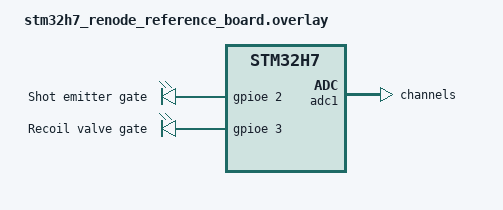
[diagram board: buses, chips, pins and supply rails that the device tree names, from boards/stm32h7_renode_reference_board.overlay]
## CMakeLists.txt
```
cmake_minimum_required(VERSION 3.20)
find_package(Zephyr REQUIRED HINTS $ENV{ZEPHYR_BASE})

project(trainer_fw LANGUAGES C)

target_include_directories(app PRIVATE
	src
	src/trigger
	src/weapon
	src/io
	src/control
	src/proto
	src/cfg
	src/can
	src/sys
	src/imu
	src/timesync
	src/strobe
)

target_sources(app PRIVATE
	src/main.c
	src/trigger/trigger_proc.c
	src/trigger/trigger_task.c
	src/weapon/rounds.c
	src/weapon/weapon_sm.c
	src/weapon/malfunction.c
	src/weapon/shotlog.c
	src/io/outputs.c
	src/io/inputs.c
	src/control/control.c
	src/proto/proto.c
	src/cfg/cfg.c
	src/cfg/cfg_store.c
	src/can/canlink.c
	src/can/lane.c
	src/sys/wdt.c
	src/sys/bit.c
	src/imu/imu_metrics.c
	src/imu/imu_task.c
	src/timesync/timesync.c
	src/strobe/strobe.c
	src/strobe/strobe_task.c
	src/shell/shell_cmds.c
)
```

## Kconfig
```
menu "Trainer weapon"

config TRAINER_MAG_CAPACITY
	int "Rounds in a full magazine"
	default 30
	range 1 100

config TRAINER_AUTO_RPM
	int "AUTO cadence (rounds per minute)"
	default 750
	range 600 900

config TRAINER_EMITTER_PULSE_US
	int "Shot emitter gate pulse width (us)"
	default 2000
	range 100 20000

config TRAINER_VALVE_PULSE_MS
	int "Recoil valve gate pulse width (ms)"
	default 20
	range 5 40

config TRAINER_TRIGGER_SAMPLE_HZ
	int "Trigger ADC sampling rate (Hz)"
	default 1000
	range 100 2000

config TRAINER_EVENT_QUEUE_LEN
	int "Control event queue length"
	default 16

config TRAINER_DEBUG_CMDS
	bool "Debug shell commands (stall threads, corrupt config)"
	help
	  Commands that deliberately break things to test the watchdog and
	  the config fallback (trainer stall, trainer cfg corrupt). Off in the
	  default image; the simulation and test image enables them with
	  app/debug.conf (scripts/build.sh).

endmenu

source "Kconfig.zephyr"
```

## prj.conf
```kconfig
# Kernel
CONFIG_MAIN_STACK_SIZE=2048
CONFIG_SYS_CLOCK_TICKS_PER_SEC=10000
CONFIG_ASSERT=y
CONFIG_POLL=y

# FPU for IMU metrics and the time-sync fit; several threads use it
CONFIG_FPU=y
CONFIG_FPU_SHARING=y

# Drivers
CONFIG_GPIO=y
CONFIG_ADC=y
CONFIG_INPUT=y
CONFIG_SENSOR=y
CONFIG_CAN=y
CONFIG_HWINFO=y

# State machine framework (hierarchical states)
CONFIG_SMF=y
CONFIG_SMF_ANCESTOR_SUPPORT=y

# Persistent configuration: settings on NVS in the QSPI storage partition
CONFIG_FLASH=y
CONFIG_FLASH_MAP=y
CONFIG_NVS=y
CONFIG_SETTINGS=y
CONFIG_SETTINGS_NVS=y
CONFIG_CRC=y

# Watchdog: one task-watchdog channel per thread, IWDG as hardware fallback
CONFIG_WATCHDOG=y
CONFIG_TASK_WDT=y
CONFIG_TASK_WDT_HW_FALLBACK=y
# control, trigger, IMU, CAN TX, lane, strobe
CONFIG_TASK_WDT_CHANNELS=6
CONFIG_REBOOT=y

# Diagnostics
CONFIG_LOG=y
# Deferred logging, but flushed promptly: wake the log thread on every
# message instead of the default 1 s batch, so test harnesses see events
# without a long delay.
CONFIG_LOG_PROCESS_TRIGGER_THRESHOLD=1
CONFIG_LOG_PROCESS_THREAD_SLEEP_MS=50
CONFIG_SHELL=y
CONFIG_SHELL_PROMPT_UART="trainer:~$ "
CONFIG_BOOT_BANNER_STRING="Booting trainer_fw"
```

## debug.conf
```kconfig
# Simulation and test image: added to prj.conf by scripts/build.sh
# (EXTRA_CONF_FILE). The default image (prj.conf alone) leaves these out.

# `trainer stall` (IT11, IT11b) and `trainer cfg corrupt` (IT08b)
CONFIG_TRAINER_DEBUG_CMDS=y
```

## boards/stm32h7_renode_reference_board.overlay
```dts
/*
 * Trainer weapon I/O on the STM32H7 Renode Reference Platform.
 *
 * Inputs use the board as it is: potentiometer (ADC1 INP2) = analog trigger,
 * SW1..SW4 (gpio-keys, INPUT_KEY_1..4) = selector, magazine, rack, tap.
 *
 * The emitter and recoil-valve gates go on free pins PE2/PE3. The board's
 * green LEDs sit on TIM3 PWM and have no LED model in Renode, so they are
 * not used. sim/trainer_io.repl attaches simulated LEDs to PE2/PE3.
 */

#include <zephyr/dt-bindings/adc/adc.h>
#include <zephyr/dt-bindings/sensor/lsm6dso.h>

/ {
	trainer_outputs {
		compatible = "gpio-leds";

		emitter_out: emitter {
			gpios = <&gpioe 2 GPIO_ACTIVE_HIGH>;
			label = "Shot emitter gate";
		};

		valve_out: valve {
			gpios = <&gpioe 3 GPIO_ACTIVE_HIGH>;
			label = "Recoil valve gate";
		};
	};

	aliases {
		trainer-emitter = &emitter_out;
		trainer-valve = &valve_out;
		trainer-status-red = &red_rgb_led;
		trainer-status-green = &green_rgb_led;
		trainer-status-blue = &blue_rgb_led;
	};
};

&gpioe {
	status = "okay";
};

/*
 * The board uses the maximum acquisition time (810.5 ADC cycles), which
 * limits trigger sampling well below 1 kHz. A short time is fine for a
 * low-impedance potentiometer and allows the 1 kHz trigger loop.
 */
&adc1 {
	channel@2 {
		zephyr,acquisition-time = <ADC_ACQ_TIME_DEFAULT>;
	};
};

/*
 * IMU for aim, cant and flinch: 208 Hz on both sensors (the board default is
 * a very low ODR). Full scale is chosen so recoil does not clip the gyro and
 * the accelerometer survives a recoil kick: +-16 g, +-2000 dps.
 */
&lsm6dso {
	accel-odr = <LSM6DSO_DT_ODR_208Hz>;
	gyro-odr = <LSM6DSO_DT_ODR_208Hz>;
	accel-range = <LSM6DSO_DT_FS_16G>;
	gyro-range = <LSM6DSO_DT_FS_2000DPS>;
};
```

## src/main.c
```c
/*
 * trainer_fw: firmware for an instrumented training weapon.
 *
 * Start order matters:
 *  1. reset reason + task watchdog
 *  2. outputs forced inactive before anything that can fire runs (SPEC R04)
 *  3. configuration (node ID) before CAN, because CAN IDs depend on it
 *  4. CAN + lane service, weapon control, emitter strobe, trigger sampling
 *  5. BIT, then INFO, so the lane learns the node is up and healthy
 */
#include <zephyr/app_version.h>
#include <zephyr/kernel.h>
#include <zephyr/logging/log.h>

#include "bit.h"
#include "canlink.h"
#include "cfg_store.h"
#include "control.h"
#include "imu_task.h"
#include "lane.h"
#include "outputs.h"
#include "strobe_task.h"
#include "trigger_task.h"
#include "wdt.h"

LOG_MODULE_REGISTER(main, LOG_LEVEL_INF);

int main(void)
{
	(void)wdt_init();
	LOG_INF("trainer_fw %s reset=%s%s%s", APP_VERSION_STRING,
		wdt_reset_reason_name(wdt_reset_reason()),
		(wdt_last_stalled_thread()[0] != '\0') ? " thread=" : "", wdt_last_stalled_thread());

	int rc = outputs_init();

	bit_note_outputs(rc);
	if (rc != 0) {
		LOG_ERR("outputs init failed (%d)", rc);
	}

	(void)cfg_store_init();
	uint8_t node = cfg_store_node_id();

	if (canlink_init(node) == 0) {
		lane_start(node);
	}

	control_start();
	strobe_start();

	rc = trigger_task_start();
	bit_note_adc(rc);

	/* A missing IMU is reported by BIT; the weapon then sits in FAULT. */
	(void)imu_task_start();

	/* Let the trigger take a few samples so BIT can see whether it is at rest. */
	k_sleep(K_MSEC(20));
	(void)bit_run();
	lane_send_info();
	LOG_INF("NODE id=%u boot=%u", node, cfg_store_boot_count());
	return 0;
}
```
